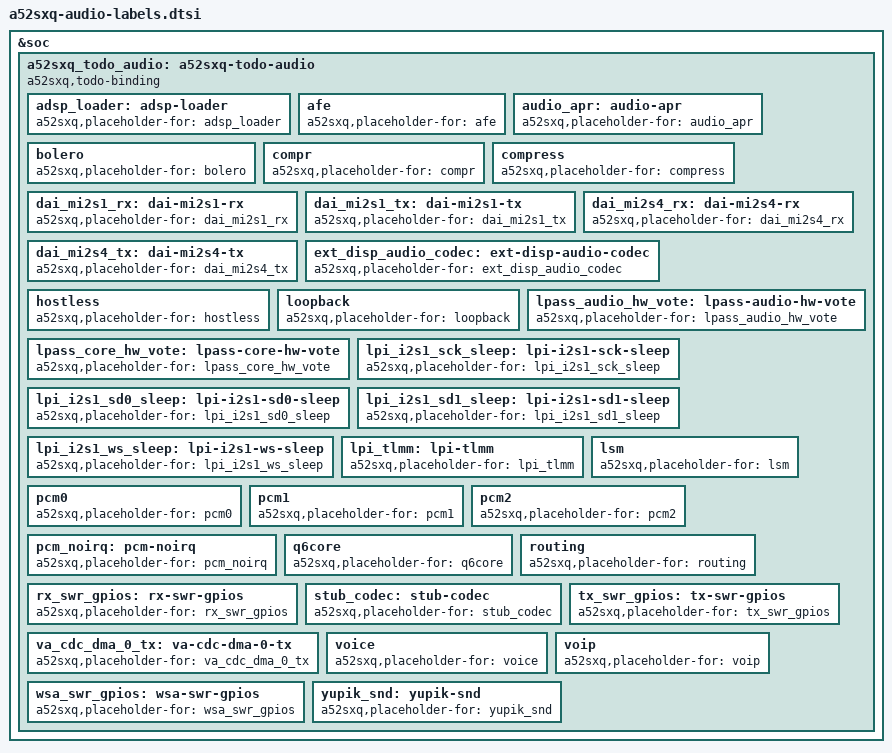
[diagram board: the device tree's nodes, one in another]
// SPDX-License-Identifier: GPL-2.0
/*
 * a52sxq board description for the Qualcomm 6.12 yupik base: placeholder labels for 'audio'
 * GENERATED by tools/gen.py from the phone's stock dtbo (5.4 bindings, values verbatim).
 * Do not edit: hand-written 6.12 changes live in a52sxq-bsp612-fixups.dtsi.
 */

/*
 * Labels of the 5.4 base that the 6.12 base does not have. Placeholders under
 * /soc/a52sxq-todo-audio (no compatible: nothing binds, children are not populated)
 * so that every reference of the phone's tree resolves. TODO-binding: replace by the
 * real 6.12 node of the owning driver and delete the placeholder.
 */
&soc {
	a52sxq_todo_audio: a52sxq-todo-audio {
		a52sxq,todo-binding;
		adsp_loader: adsp-loader {
			a52sxq,placeholder-for = "adsp_loader";
		};
		afe: afe {
			a52sxq,placeholder-for = "afe";
		};
		audio_apr: audio-apr {
			a52sxq,placeholder-for = "audio_apr";
		};
		bolero: bolero {
			a52sxq,placeholder-for = "bolero";
		};
		compr: compr {
			a52sxq,placeholder-for = "compr";
		};
		compress: compress {
			a52sxq,placeholder-for = "compress";
		};
		dai_mi2s1_rx: dai-mi2s1-rx {
			a52sxq,placeholder-for = "dai_mi2s1_rx";
		};
		dai_mi2s1_tx: dai-mi2s1-tx {
			a52sxq,placeholder-for = "dai_mi2s1_tx";
		};
		dai_mi2s4_rx: dai-mi2s4-rx {
			a52sxq,placeholder-for = "dai_mi2s4_rx";
		};
		dai_mi2s4_tx: dai-mi2s4-tx {
			a52sxq,placeholder-for = "dai_mi2s4_tx";
		};
		ext_disp_audio_codec: ext-disp-audio-codec {
			a52sxq,placeholder-for = "ext_disp_audio_codec";
		};
		hostless: hostless {
			a52sxq,placeholder-for = "hostless";
		};
		loopback: loopback {
			a52sxq,placeholder-for = "loopback";
		};
		lpass_audio_hw_vote: lpass-audio-hw-vote {
			a52sxq,placeholder-for = "lpass_audio_hw_vote";
		};
		lpass_core_hw_vote: lpass-core-hw-vote {
			a52sxq,placeholder-for = "lpass_core_hw_vote";
		};
		lpi_i2s1_sck_sleep: lpi-i2s1-sck-sleep {
			a52sxq,placeholder-for = "lpi_i2s1_sck_sleep";
		};
		lpi_i2s1_sd0_sleep: lpi-i2s1-sd0-sleep {
			a52sxq,placeholder-for = "lpi_i2s1_sd0_sleep";
		};
		lpi_i2s1_sd1_sleep: lpi-i2s1-sd1-sleep {
			a52sxq,placeholder-for = "lpi_i2s1_sd1_sleep";
		};
		lpi_i2s1_ws_sleep: lpi-i2s1-ws-sleep {
			a52sxq,placeholder-for = "lpi_i2s1_ws_sleep";
		};
		lpi_tlmm: lpi-tlmm {
			a52sxq,placeholder-for = "lpi_tlmm";
		};
		lsm: lsm {
			a52sxq,placeholder-for = "lsm";
		};
		pcm0: pcm0 {
			a52sxq,placeholder-for = "pcm0";
		};
		pcm1: pcm1 {
			a52sxq,placeholder-for = "pcm1";
		};
		pcm2: pcm2 {
			a52sxq,placeholder-for = "pcm2";
		};
		pcm_noirq: pcm-noirq {
			a52sxq,placeholder-for = "pcm_noirq";
		};
		q6core: q6core {
			a52sxq,placeholder-for = "q6core";
		};
		routing: routing {
			a52sxq,placeholder-for = "routing";
		};
		rx_swr_gpios: rx-swr-gpios {
			a52sxq,placeholder-for = "rx_swr_gpios";
		};
		stub_codec: stub-codec {
			a52sxq,placeholder-for = "stub_codec";
		};
		tx_swr_gpios: tx-swr-gpios {
			a52sxq,placeholder-for = "tx_swr_gpios";
		};
		va_cdc_dma_0_tx: va-cdc-dma-0-tx {
			a52sxq,placeholder-for = "va_cdc_dma_0_tx";
		};
		voice: voice {
			a52sxq,placeholder-for = "voice";
		};
		voip: voip {
			a52sxq,placeholder-for = "voip";
		};
		wsa_swr_gpios: wsa-swr-gpios {
			a52sxq,placeholder-for = "wsa_swr_gpios";
		};
		yupik_snd: yupik-snd {
			a52sxq,placeholder-for = "yupik_snd";
		};
	};
};

